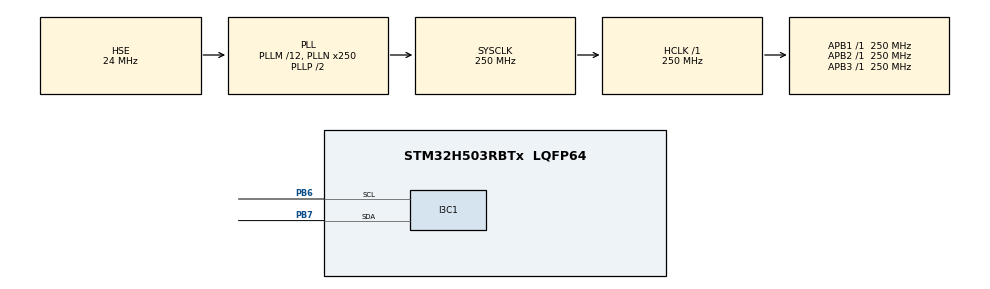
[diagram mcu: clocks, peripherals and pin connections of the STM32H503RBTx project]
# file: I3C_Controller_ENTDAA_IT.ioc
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I3C1.BusFreeDuration=402
I3C1.DutyCycleI3C=50
I3C1.FrequencyI3C=12500
I3C1.Register0=0x00590909
I3C1.Register1=0x103200f8
I3C1.SCLI3CHighDuration=0x09
I3C1.SCLODLowDuration=0x59
I3C1.SCLPPLowDuration=0x09
I3C1.SDAHoldTime=HAL_I3C_SDA_HOLD_TIME_1_5
I3C1.StallTime=0
I3C1.hexBusFreeDuration=0x32
I3C1.hexBusIdleDuration=0xf8
Mcu.Family=STM32H5
Mcu.Name=STM32H503RBTx
Mcu.Package=LQFP64
NVIC.I3C1_ER_IRQn=true\:0\:0\:false\:false\:true\:true\:true\:true
NVIC.I3C1_EV_IRQn=true\:0\:0\:false\:false\:true\:true\:true\:true
NVIC.PriorityGroup=NVIC_PRIORITYGROUP_4
PB6.Mode=Controller
PB6.Signal=I3C1_SCL
PB7.Mode=Controller
PB7.Signal=I3C1_SDA
PH0-OSC_IN(PH0).Mode=HSE-External-Oscillator
PH0-OSC_IN(PH0).Signal=RCC_OSC_IN
PH1-OSC_OUT(PH1).Mode=HSE-External-Oscillator
PH1-OSC_OUT(PH1).Signal=RCC_OSC_OUT
ProjectManager.HeapSize=0x200
ProjectManager.StackSize=0x400
ProjectManager.TargetToolchain=EWARM V9.20
RCC.ADCFreq_Value=250000000
RCC.AHBFreq_Value=250000000
RCC.APB1Freq_Value=250000000
RCC.APB1TimFreq_Value=250000000
RCC.APB2Freq_Value=250000000
RCC.APB2TimFreq_Value=250000000
RCC.APB3Freq_Value=250000000
RCC.CSI_VALUE=4000000
RCC.CortexFreq_Value=250000000
RCC.EPOD_VALUE=24000000
RCC.HCLKFreq_Value=250000000
RCC.HSE_VALUE=24000000
RCC.HSI48_VALUE=48000000
RCC.HSIDiv=RCC_HSI_DIV1
RCC.HSI_VALUE=64000000
RCC.LSE_VALUE=32768
RCC.LSIRC_VALUE=32000
RCC.PLL1R=1
RCC.PLL2FRACN=0
RCC.PLLFRACN=0
RCC.PLLM=12
RCC.PLLN=250
RCC.PLLSourceVirtual=RCC_PLL1_SOURCE_HSE
RCC.PWR_Regulator_Voltage_Scale=PWR_REGULATOR_VOLTAGE_SCALE0
RCC.SYSCLKFreq_VALUE=250000000
RCC.SYSCLKSource=RCC_SYSCLKSOURCE_PLLCLK
RCC.USBFreq_Value=48000000
RCC.VCOOutputFreq_Value=500000000
VP_ICACHE_VS_ICACHE.Mode=DefaultMode
VP_PWR_VS_SECSignals.Mode=Security/Privilege
board=custom

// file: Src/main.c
/* USER CODE BEGIN Header */
/**
  ******************************************************************************
  * @file    I3C/I3C_Controller_ENTDAA_IT/Src/main.c
  * @author  MCD Application Team
  * @brief   This sample code shows how to use STM32H5xx I3C HAL API to
  *          manage a Dynamic Address Assignment procedure between a Controller
  *          and one or two Targets with a communication process based
  *          on Interrupt transfer.
  *          The communication is done using 2 or 3 Boards.
  ******************************************************************************
  * @attention
  *
  * Copyright (c) 2023 STMicroelectronics.
  * All rights reserved.
  *
  * This software is licensed under terms that can be found in the LICENSE file
  * in the root directory of this software component.
  * If no LICENSE file comes with this software, it is provided AS-IS.
  *
  ******************************************************************************
  */
/* USER CODE END Header */
#include "main.h"

/* USER CODE BEGIN Includes */
#include "desc_target1.h"
#include "desc_target2.h"
/* USER CODE END Includes */

I3C_HandleTypeDef hi3c1;

/* USER CODE BEGIN PV */
/* Number of Targets detected during DAA procedure */
__IO uint32_t uwTargetCount = 0;

/* Array contain targets descriptor */
TargetDesc_TypeDef *aTargetDesc[2] = \
                          {
                            &TargetDesc1,       /* DEVICE_ID1 */
                            &TargetDesc2        /* DEVICE_ID2 */
                          };

/* Buffer that contain payload data, mean PID, BCR, DCR */
uint8_t aPayloadBuffer[64*COUNTOF(aTargetDesc)];
/* USER CODE END PV */

void SystemClock_Config(void);
static void MX_GPIO_Init(void);
static void MX_I3C1_Init(void);
static void MX_ICACHE_Init(void);

int main(void)
{

  /* MCU Configuration--------------------------------------------------------*/

  /* Reset of all peripherals, Initializes the Flash interface and the Systick. */
  HAL_Init();

  /* Configure the system clock */
  SystemClock_Config();

  /* Initialize all configured peripherals */
  MX_GPIO_Init();
  MX_I3C1_Init();
  MX_ICACHE_Init();
  /* USER CODE BEGIN 2 */
  /* Configure LED2 */
  BSP_LED_Init(LED2);

  /* Configure USER push-button */
  BSP_PB_Init(BUTTON_USER,BUTTON_MODE_GPIO);

  /* Wait for USER push-button press before starting the Communication */
  while (BSP_PB_GetState(BUTTON_USER) != GPIO_PIN_RESET)
  {
  }

  /* Wait for USER push-button release before starting the Communication */
  while (BSP_PB_GetState(BUTTON_USER) != GPIO_PIN_SET)
  {
  }

  /*##- Start the transmission process ###################################*/
  /* Assign dynamic address processus */
  if (HAL_I3C_Ctrl_DynAddrAssign_IT(&hi3c1, I3C_ONLY_ENTDAA) != HAL_OK)
  {
    /* Error_Handler() function is called when error occurs. */
    Error_Handler();
  }

  /*##- Wait for the end of the transfer #################################*/
  /*  Before starting a new communication transfer, you need to check the current
  state of the peripheral; if it's busy you need to wait for the end of current
  transfer before starting a new one.
  For simplicity reasons, this example is just waiting till the end of the
  transfer, but application may perform other tasks while transfer operation
  is ongoing. */
  while (HAL_I3C_GetState(&hi3c1) != HAL_I3C_STATE_READY)
  {
  }
  /* USER CODE END 2 */

  /* Infinite loop */
  while (1)
  {

  }
}

void SystemClock_Config(void)
{
  RCC_OscInitTypeDef RCC_OscInitStruct = {0};
  RCC_ClkInitTypeDef RCC_ClkInitStruct = {0};

  /** Configure the main internal regulator output voltage
  */
  __HAL_PWR_VOLTAGESCALING_CONFIG(PWR_REGULATOR_VOLTAGE_SCALE0);

  while(!__HAL_PWR_GET_FLAG(PWR_FLAG_VOSRDY)) {}

  /** Initializes the RCC Oscillators according to the specified parameters
  * in the RCC_OscInitTypeDef structure.
  */
  RCC_OscInitStruct.OscillatorType = RCC_OSCILLATORTYPE_HSE;
  RCC_OscInitStruct.HSEState = RCC_HSE_ON;
  RCC_OscInitStruct.PLL.PLLState = RCC_PLL_ON;
  RCC_OscInitStruct.PLL.PLLSource = RCC_PLL1_SOURCE_HSE;
  RCC_OscInitStruct.PLL.PLLM = 12;
  RCC_OscInitStruct.PLL.PLLN = 250;
  RCC_OscInitStruct.PLL.PLLP = 2;
  RCC_OscInitStruct.PLL.PLLQ = 2;
  RCC_OscInitStruct.PLL.PLLR = 1;
  RCC_OscInitStruct.PLL.PLLRGE = RCC_PLL1_VCIRANGE_1;
  RCC_OscInitStruct.PLL.PLLVCOSEL = RCC_PLL1_VCORANGE_WIDE;
  RCC_OscInitStruct.PLL.PLLFRACN = 0;
  if (HAL_RCC_OscConfig(&RCC_OscInitStruct) != HAL_OK)
  {
    Error_Handler();
  }

  /** Initializes the CPU, AHB and APB buses clocks
  */
  RCC_ClkInitStruct.ClockType = RCC_CLOCKTYPE_HCLK|RCC_CLOCKTYPE_SYSCLK
                              |RCC_CLOCKTYPE_PCLK1|RCC_CLOCKTYPE_PCLK2
                              |RCC_CLOCKTYPE_PCLK3;
  RCC_ClkInitStruct.SYSCLKSource = RCC_SYSCLKSOURCE_PLLCLK;
  RCC_ClkInitStruct.AHBCLKDivider = RCC_SYSCLK_DIV1;
  RCC_ClkInitStruct.APB1CLKDivider = RCC_HCLK_DIV1;
  RCC_ClkInitStruct.APB2CLKDivider = RCC_HCLK_DIV1;
  RCC_ClkInitStruct.APB3CLKDivider = RCC_HCLK_DIV1;

  if (HAL_RCC_ClockConfig(&RCC_ClkInitStruct, FLASH_LATENCY_5) != HAL_OK)
  {
    Error_Handler();
  }

  /** Configure the programming delay
  */
  __HAL_FLASH_SET_PROGRAM_DELAY(FLASH_PROGRAMMING_DELAY_2);
}

static void MX_I3C1_Init(void)
{

  I3C_FifoConfTypeDef sFifoConfig = {0};
  I3C_CtrlConfTypeDef sCtrlConfig = {0};

  hi3c1.Instance = I3C1;
  hi3c1.Mode = HAL_I3C_MODE_CONTROLLER;
  hi3c1.Init.CtrlBusCharacteristic.SDAHoldTime = HAL_I3C_SDA_HOLD_TIME_1_5;
  hi3c1.Init.CtrlBusCharacteristic.WaitTime = HAL_I3C_OWN_ACTIVITY_STATE_0;
  hi3c1.Init.CtrlBusCharacteristic.SCLPPLowDuration = 0x09;
  hi3c1.Init.CtrlBusCharacteristic.SCLI3CHighDuration = 0x09;
  hi3c1.Init.CtrlBusCharacteristic.SCLODLowDuration = 0x59;
  hi3c1.Init.CtrlBusCharacteristic.SCLI2CHighDuration = 0x00;
  hi3c1.Init.CtrlBusCharacteristic.BusFreeDuration = 0x32;
  hi3c1.Init.CtrlBusCharacteristic.BusIdleDuration = 0xf8;
  if (HAL_I3C_Init(&hi3c1) != HAL_OK)
  {
    Error_Handler();
  }

  /** Configure FIFO
  */
  sFifoConfig.RxFifoThreshold = HAL_I3C_RXFIFO_THRESHOLD_1_4;
  sFifoConfig.TxFifoThreshold = HAL_I3C_TXFIFO_THRESHOLD_1_4;
  sFifoConfig.ControlFifo = HAL_I3C_CONTROLFIFO_DISABLE;
  sFifoConfig.StatusFifo = HAL_I3C_STATUSFIFO_DISABLE;
  if (HAL_I3C_SetConfigFifo(&hi3c1, &sFifoConfig) != HAL_OK)
  {
    Error_Handler();
  }

  /** Configure controller
  */
  sCtrlConfig.DynamicAddr = 0;
  sCtrlConfig.StallTime = 0x00;
  sCtrlConfig.HotJoinAllowed = DISABLE;
  sCtrlConfig.ACKStallState = DISABLE;
  sCtrlConfig.CCCStallState = DISABLE;
  sCtrlConfig.TxStallState = DISABLE;
  sCtrlConfig.RxStallState = DISABLE;
  sCtrlConfig.HighKeeperSDA = DISABLE;
  if (HAL_I3C_Ctrl_Config(&hi3c1, &sCtrlConfig) != HAL_OK)
  {
    Error_Handler();
  }

}

static void MX_ICACHE_Init(void)
{

  /** Enable instruction cache (default 2-ways set associative cache)
  */
  if (HAL_ICACHE_Enable() != HAL_OK)
  {
    Error_Handler();
  }

}

static void MX_GPIO_Init(void)
{

  /* GPIO Ports Clock Enable */
  __HAL_RCC_GPIOH_CLK_ENABLE();
  __HAL_RCC_GPIOB_CLK_ENABLE();

}

/* USER CODE BEGIN 4 */
/**
  * @brief I3C target request a dynamic address callback.
  *        The main objective of this user function is to check if a target request a dynamic address.
  *        if the case we should assign a dynamic address to the target.
  * @par Called functions
  * - HAL_I3C_TgtReqDynamicAddrCallback()
  * - HAL_I3C_Ctrl_SetDynamicAddress()
  * @retval None
  */
void HAL_I3C_TgtReqDynamicAddrCallback(I3C_HandleTypeDef *hi3c, uint64_t targetPayload)
{
  /* Update Payload on aTargetDesc */
  aTargetDesc[uwTargetCount]->TARGET_BCR_DCR_PID = targetPayload;

  /* Send associated dynamic address */
  HAL_I3C_Ctrl_SetDynAddr(hi3c, aTargetDesc[uwTargetCount++]->DYNAMIC_ADDR);
}

/**
  * @brief  Controller dynamic address assignment Complete callback.
  * @param  hi3c : [IN] Pointer to an I3C_HandleTypeDef structure that contains the configuration information
  *                     for the specified I3C.
  * @retval None
  */
void HAL_I3C_CtrlDAACpltCallback(I3C_HandleTypeDef *hi3c)
{
  /* Turn LED2 on: Transfer in Transmission process is correct */
  BSP_LED_On(LED2);
}
/* USER CODE END 4 */

void Error_Handler(void)
{
  /* USER CODE BEGIN Error_Handler_Debug */
  /* Error if LED2 is slowly blinking (1 sec. period) */
  while (1)
  {
    BSP_LED_Toggle(LED2);
    HAL_Delay(1000);
  }
  /* USER CODE END Error_Handler_Debug */
}
